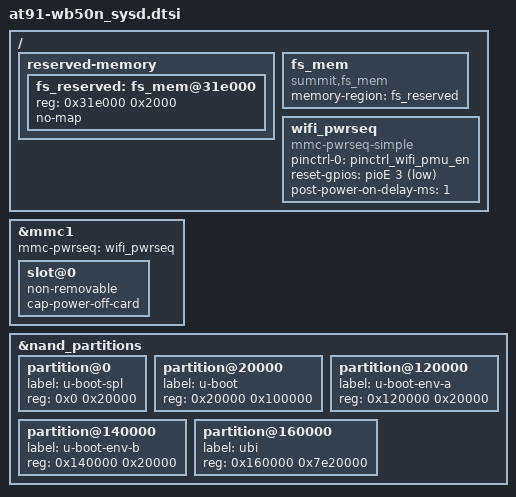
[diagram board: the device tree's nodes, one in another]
// SPDX-License-Identifier: GPL-2.0
/*
 * at91-wb50n_sysd.dtsi - Device Tree include file for WB50N sysd CPU module
 *
 *  Copyright (C) 2018-2020 Ezurio
 *
 */

#include "at91-wb50n_common.dtsi"

/ {
	reserved-memory {
		#address-cells = <1>;
		#size-cells = <1>;
		ranges;
		fs_reserved: fs_mem@31e000{
			reg = <0x31e000 0x2000>;
			no-map;
		};
	};

	fs_mem {
		compatible = "summit,fs_mem";
		memory-region = <&fs_reserved>;
	};

	wifi_pwrseq: wifi_pwrseq {
		pinctrl-names = "default";
		pinctrl-0 = <&pinctrl_wifi_pmu_en>;

		compatible = "mmc-pwrseq-simple";
		reset-gpios = <&pioE 3 GPIO_ACTIVE_LOW>;
		post-power-on-delay-ms = <1>;
	};
};

&mmc1 {
	mmc-pwrseq = <&wifi_pwrseq>;

	slot@0 {
		non-removable;
		cap-power-off-card;
	};
};

&nand_partitions {
	partition@0 {
		label = "u-boot-spl";
		reg = <0x0 0x20000>;
	};

	partition@20000 {
		label = "u-boot";
		reg = <0x20000 0x100000>;
	};

	partition@120000 {
		label = "u-boot-env-a";
		reg = <0x120000 0x20000>;
	};

	partition@140000 {
		label = "u-boot-env-b";
		reg = <0x140000 0x20000>;
	};

	partition@160000 {
		label = "ubi";
		reg = <0x160000 0x7e20000>;
	};
};
